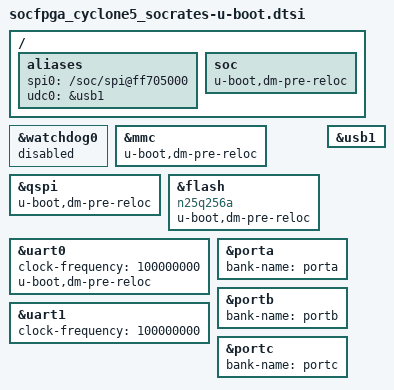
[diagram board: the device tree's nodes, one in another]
// SPDX-License-Identifier: GPL-2.0+
/*
 * U-Boot additions
 *
 * Copyright (C) 2014 Steffen Trumtrar <s.trumtrar@pengutronix.de>
 * Copyright (c) 2018 Simon Goldschmidt
 */

/{
	aliases {
		spi0 = "/soc/spi@ff705000";
		udc0 = &usb1;
	};

	soc {
		u-boot,dm-pre-reloc;
	};
};

&watchdog0 {
	status = "disabled";
};

&mmc {
	u-boot,dm-pre-reloc;
};

&qspi {
	u-boot,dm-pre-reloc;
};

&flash {
	compatible = "n25q256a", "spi-flash";
	u-boot,dm-pre-reloc;
};

&uart0 {
	clock-frequency = <100000000>;
	u-boot,dm-pre-reloc;
};

&uart1 {
	clock-frequency = <100000000>;
};

&usb1 {
	status = "okay";
};

&porta {
	bank-name = "porta";
};

&portb {
	bank-name = "portb";
};

&portc {
	bank-name = "portc";
};
